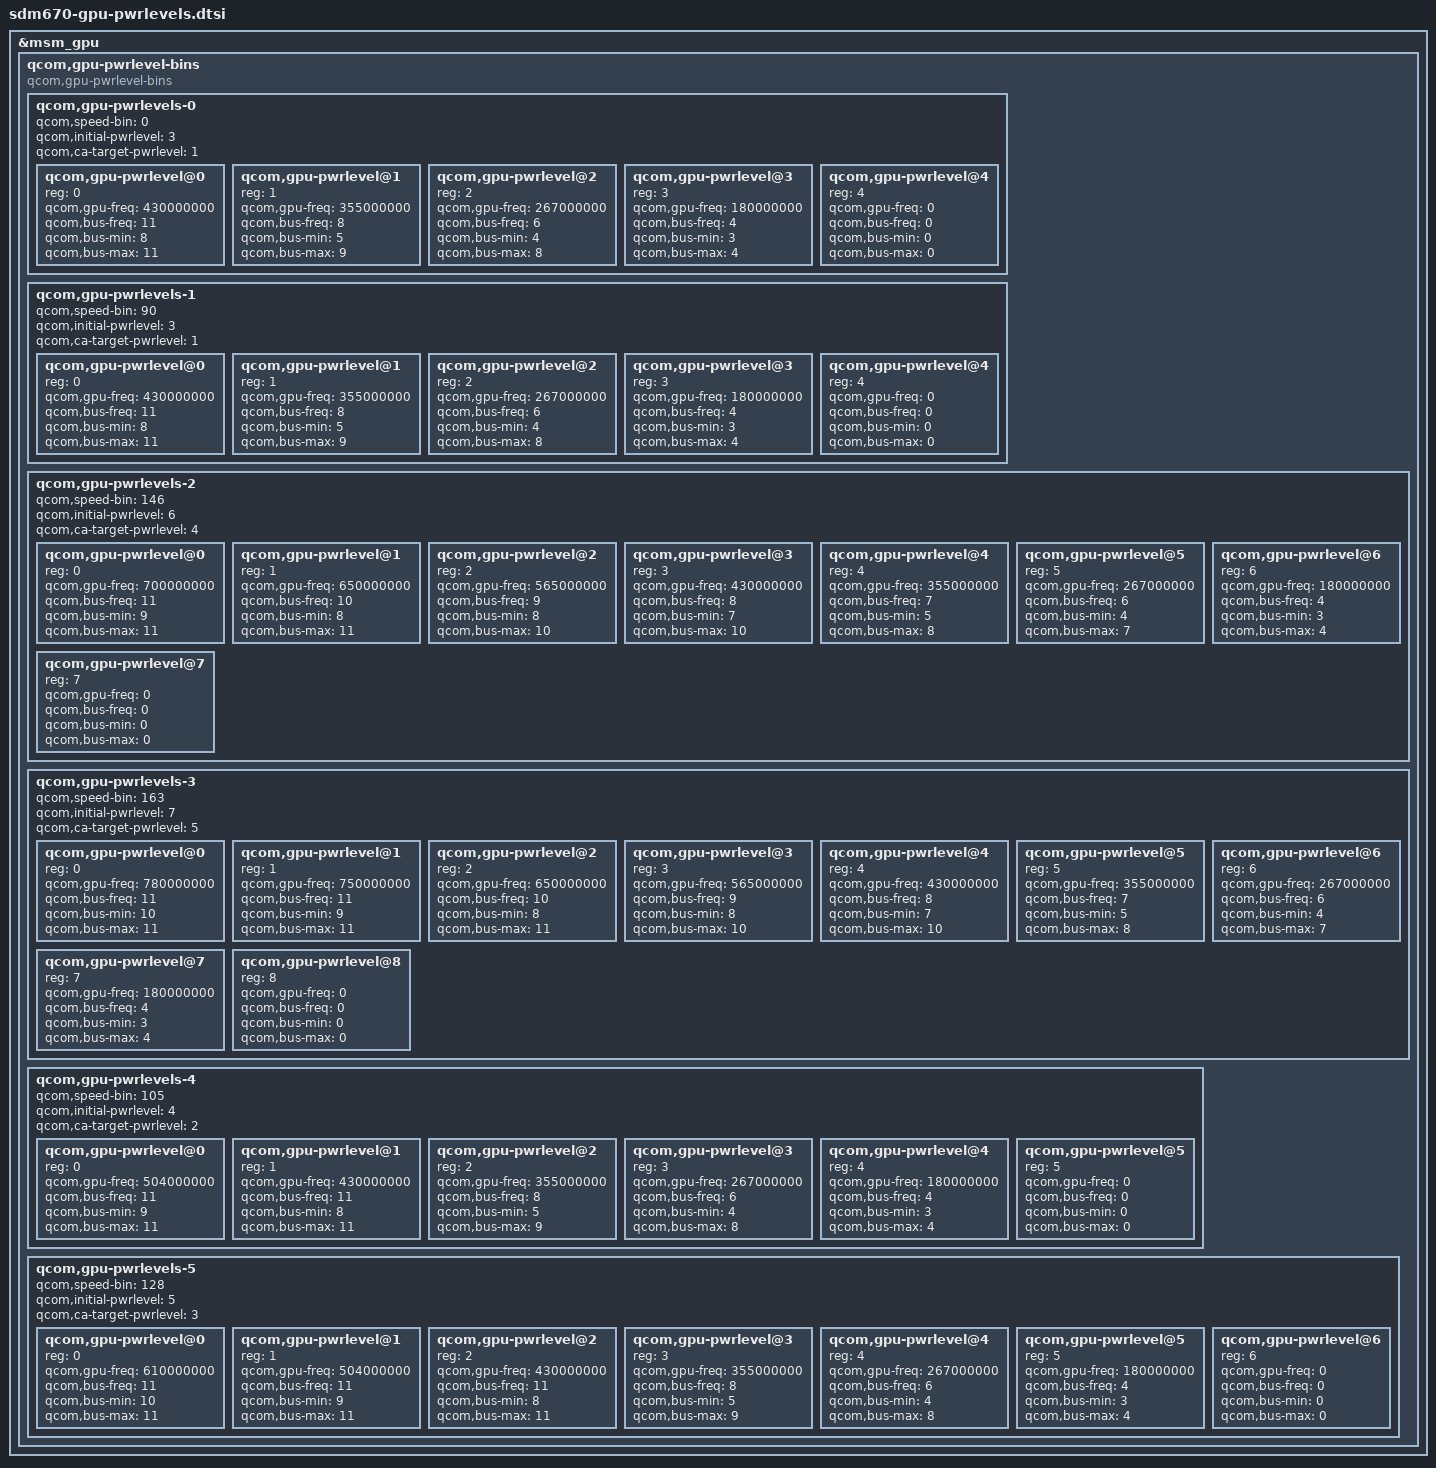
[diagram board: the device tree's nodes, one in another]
&msm_gpu {
	qcom,gpu-pwrlevel-bins {
		#address-cells = <1>;
		#size-cells = <0>;

		compatible="qcom,gpu-pwrlevel-bins";

		qcom,gpu-pwrlevels-0 {
			#address-cells = <1>;
			#size-cells = <0>;

			qcom,speed-bin = <0>;

			qcom,initial-pwrlevel = <3>;
			qcom,ca-target-pwrlevel = <1>;

			/* SVS_L1 */
			qcom,gpu-pwrlevel@0 {
				reg = <0>;
				qcom,gpu-freq = <430000000>;
				qcom,bus-freq = <11>;
				qcom,bus-min = <8>;
				qcom,bus-max = <11>;
			};

			/* SVS */
			qcom,gpu-pwrlevel@1 {
				reg = <1>;
				qcom,gpu-freq = <355000000>;
				qcom,bus-freq = <8>;
				qcom,bus-min = <5>;
				qcom,bus-max = <9>;
			};

			/* LOW SVS */
			qcom,gpu-pwrlevel@2 {
				reg = <2>;
				qcom,gpu-freq = <267000000>;
				qcom,bus-freq = <6>;
				qcom,bus-min = <4>;
				qcom,bus-max = <8>;
			};

			/* MIN SVS */
			qcom,gpu-pwrlevel@3 {
				reg = <3>;
				qcom,gpu-freq = <180000000>;
				qcom,bus-freq = <4>;
				qcom,bus-min = <3>;
				qcom,bus-max = <4>;
			};

			/* XO */
			qcom,gpu-pwrlevel@4 {
				reg = <4>;
				qcom,gpu-freq = <0>;
				qcom,bus-freq = <0>;
				qcom,bus-min = <0>;
				qcom,bus-max = <0>;
			};
		};

		qcom,gpu-pwrlevels-1 {
			#address-cells = <1>;
			#size-cells = <0>;

			qcom,speed-bin = <90>;

			qcom,initial-pwrlevel = <3>;
			qcom,ca-target-pwrlevel = <1>;

			/* SVS_L1 */
			qcom,gpu-pwrlevel@0 {
				reg = <0>;
				qcom,gpu-freq = <430000000>;
				qcom,bus-freq = <11>;
				qcom,bus-min = <8>;
				qcom,bus-max = <11>;
			};

			/* SVS */
			qcom,gpu-pwrlevel@1 {
				reg = <1>;
				qcom,gpu-freq = <355000000>;
				qcom,bus-freq = <8>;
				qcom,bus-min = <5>;
				qcom,bus-max = <9>;
			};

			/* LOW SVS */
			qcom,gpu-pwrlevel@2 {
				reg = <2>;
				qcom,gpu-freq = <267000000>;
				qcom,bus-freq = <6>;
				qcom,bus-min = <4>;
				qcom,bus-max = <8>;
			};

			/* MIN SVS */
			qcom,gpu-pwrlevel@3 {
				reg = <3>;
				qcom,gpu-freq = <180000000>;
				qcom,bus-freq = <4>;
				qcom,bus-min = <3>;
				qcom,bus-max = <4>;
			};

			/* XO */
			qcom,gpu-pwrlevel@4 {
				reg = <4>;
				qcom,gpu-freq = <0>;
				qcom,bus-freq = <0>;
				qcom,bus-min = <0>;
				qcom,bus-max = <0>;
			};

		};

		qcom,gpu-pwrlevels-2 {
			#address-cells = <1>;
			#size-cells = <0>;

			qcom,speed-bin = <146>;

			qcom,initial-pwrlevel = <6>;
			qcom,ca-target-pwrlevel = <4>;

			/* TURBO */
			qcom,gpu-pwrlevel@0 {
				reg = <0>;
				qcom,gpu-freq = <700000000>;
				qcom,bus-freq = <11>;
				qcom,bus-min = <9>;
				qcom,bus-max = <11>;
			};

			/* NOM_L1 */
			qcom,gpu-pwrlevel@1 {
				reg = <1>;
				qcom,gpu-freq = <650000000>;
				qcom,bus-freq = <10>;
				qcom,bus-min = <8>;
				qcom,bus-max = <11>;
			};

			/* NOM */
			qcom,gpu-pwrlevel@2 {
				reg = <2>;
				qcom,gpu-freq = <565000000>;
				qcom,bus-freq = <9>;
				qcom,bus-min = <8>;
				qcom,bus-max = <10>;
			};

			/* SVS_L1 */
			qcom,gpu-pwrlevel@3 {
				reg = <3>;
				qcom,gpu-freq = <430000000>;
				qcom,bus-freq = <8>;
				qcom,bus-min = <7>;
				qcom,bus-max = <10>;
			};

			/* SVS */
			qcom,gpu-pwrlevel@4 {
				reg = <4>;
				qcom,gpu-freq = <355000000>;
				qcom,bus-freq = <7>;
				qcom,bus-min = <5>;
				qcom,bus-max = <8>;
			};

			/* LOW SVS */
			qcom,gpu-pwrlevel@5 {
				reg = <5>;
				qcom,gpu-freq = <267000000>;
				qcom,bus-freq = <6>;
				qcom,bus-min = <4>;
				qcom,bus-max = <7>;
			};

			/* MIN SVS */
			qcom,gpu-pwrlevel@6 {
				reg = <6>;
				qcom,gpu-freq = <180000000>;
				qcom,bus-freq = <4>;
				qcom,bus-min = <3>;
				qcom,bus-max = <4>;
			};

			/* XO */
			qcom,gpu-pwrlevel@7 {
				reg = <7>;
				qcom,gpu-freq = <0>;
				qcom,bus-freq = <0>;
				qcom,bus-min = <0>;
				qcom,bus-max = <0>;
			};

		};

		qcom,gpu-pwrlevels-3 {
			#address-cells = <1>;
			#size-cells = <0>;

			qcom,speed-bin = <163>;

			qcom,initial-pwrlevel = <7>;
			qcom,ca-target-pwrlevel = <5>;

			/* TURBO_L1 */
			qcom,gpu-pwrlevel@0 {
				reg = <0>;
				qcom,gpu-freq = <780000000>;
				qcom,bus-freq = <11>;
				qcom,bus-min = <10>;
				qcom,bus-max = <11>;
			};

			/* TURBO */
			qcom,gpu-pwrlevel@1 {
				reg = <1>;
				qcom,gpu-freq = <750000000>;
				qcom,bus-freq = <11>;
				qcom,bus-min = <9>;
				qcom,bus-max = <11>;
			};

			/* NOM_L1 */
			qcom,gpu-pwrlevel@2 {
				reg = <2>;
				qcom,gpu-freq = <650000000>;
				qcom,bus-freq = <10>;
				qcom,bus-min = <8>;
				qcom,bus-max = <11>;
			};

			/* NOM */
			qcom,gpu-pwrlevel@3 {
				reg = <3>;
				qcom,gpu-freq = <565000000>;
				qcom,bus-freq = <9>;
				qcom,bus-min = <8>;
				qcom,bus-max = <10>;
			};

			/* SVS_L1 */
			qcom,gpu-pwrlevel@4 {
				reg = <4>;
				qcom,gpu-freq = <430000000>;
				qcom,bus-freq = <8>;
				qcom,bus-min = <7>;
				qcom,bus-max = <10>;
			};

			/* SVS */
			qcom,gpu-pwrlevel@5 {
				reg = <5>;
				qcom,gpu-freq = <355000000>;
				qcom,bus-freq = <7>;
				qcom,bus-min = <5>;
				qcom,bus-max = <8>;
			};

			/* LOW SVS */
			qcom,gpu-pwrlevel@6 {
				reg = <6>;
				qcom,gpu-freq = <267000000>;
				qcom,bus-freq = <6>;
				qcom,bus-min = <4>;
				qcom,bus-max = <7>;
			};

			/* MIN SVS */
			qcom,gpu-pwrlevel@7 {
				reg = <7>;
				qcom,gpu-freq = <180000000>;
				qcom,bus-freq = <4>;
				qcom,bus-min = <3>;
				qcom,bus-max = <4>;
			};

			/* XO */
			qcom,gpu-pwrlevel@8 {
				reg = <8>;
				qcom,gpu-freq = <0>;
				qcom,bus-freq = <0>;
				qcom,bus-min = <0>;
				qcom,bus-max = <0>;
			};
		};

		qcom,gpu-pwrlevels-4 {
			#address-cells = <1>;
			#size-cells = <0>;

			qcom,speed-bin = <105>;

			qcom,initial-pwrlevel = <4>;
			qcom,ca-target-pwrlevel = <2>;

			/* NOM */
			qcom,gpu-pwrlevel@0 {
				reg = <0>;
				qcom,gpu-freq = <504000000>;
				qcom,bus-freq = <11>;
				qcom,bus-min = <9>;
				qcom,bus-max = <11>;
			};

			/* SVS_L1 */
			qcom,gpu-pwrlevel@1 {
				reg = <1>;
				qcom,gpu-freq = <430000000>;
				qcom,bus-freq = <11>;
				qcom,bus-min = <8>;
				qcom,bus-max = <11>;
			};

			/* SVS */
			qcom,gpu-pwrlevel@2 {
				reg = <2>;
				qcom,gpu-freq = <355000000>;
				qcom,bus-freq = <8>;
				qcom,bus-min = <5>;
				qcom,bus-max = <9>;
			};

			/* LOW SVS */
			qcom,gpu-pwrlevel@3 {
				reg = <3>;
				qcom,gpu-freq = <267000000>;
				qcom,bus-freq = <6>;
				qcom,bus-min = <4>;
				qcom,bus-max = <8>;
			};

			/* MIN SVS */
			qcom,gpu-pwrlevel@4 {
				reg = <4>;
				qcom,gpu-freq = <180000000>;
				qcom,bus-freq = <4>;
				qcom,bus-min = <3>;
				qcom,bus-max = <4>;
			};

			/* XO */
			qcom,gpu-pwrlevel@5 {
				reg = <5>;
				qcom,gpu-freq = <0>;
				qcom,bus-freq = <0>;
				qcom,bus-min = <0>;
				qcom,bus-max = <0>;
			};
		};

		qcom,gpu-pwrlevels-5 {
			#address-cells = <1>;
			#size-cells = <0>;

			qcom,speed-bin = <128>;

			qcom,initial-pwrlevel = <5>;
			qcom,ca-target-pwrlevel = <3>;

			/* NOM_L1 */
			qcom,gpu-pwrlevel@0 {
				reg = <0>;
				qcom,gpu-freq = <610000000>;
				qcom,bus-freq = <11>;
				qcom,bus-min = <10>;
				qcom,bus-max = <11>;
			};

			/* NOM */
			qcom,gpu-pwrlevel@1 {
				reg = <1>;
				qcom,gpu-freq = <504000000>;
				qcom,bus-freq = <11>;
				qcom,bus-min = <9>;
				qcom,bus-max = <11>;
			};

			/* SVS_L1 */
			qcom,gpu-pwrlevel@2 {
				reg = <2>;
				qcom,gpu-freq = <430000000>;
				qcom,bus-freq = <11>;
				qcom,bus-min = <8>;
				qcom,bus-max = <11>;
			};

			/* SVS */
			qcom,gpu-pwrlevel@3 {
				reg = <3>;
				qcom,gpu-freq = <355000000>;
				qcom,bus-freq = <8>;
				qcom,bus-min = <5>;
				qcom,bus-max = <9>;
			};

			/* LOW SVS */
			qcom,gpu-pwrlevel@4 {
				reg = <4>;
				qcom,gpu-freq = <267000000>;
				qcom,bus-freq = <6>;
				qcom,bus-min = <4>;
				qcom,bus-max = <8>;
			};

			/* MIN SVS */
			qcom,gpu-pwrlevel@5 {
				reg = <5>;
				qcom,gpu-freq = <180000000>;
				qcom,bus-freq = <4>;
				qcom,bus-min = <3>;
				qcom,bus-max = <4>;
			};

			/* XO */
			qcom,gpu-pwrlevel@6 {
				reg = <6>;
				qcom,gpu-freq = <0>;
				qcom,bus-freq = <0>;
				qcom,bus-min = <0>;
				qcom,bus-max = <0>;
			};
		};
	};
};
